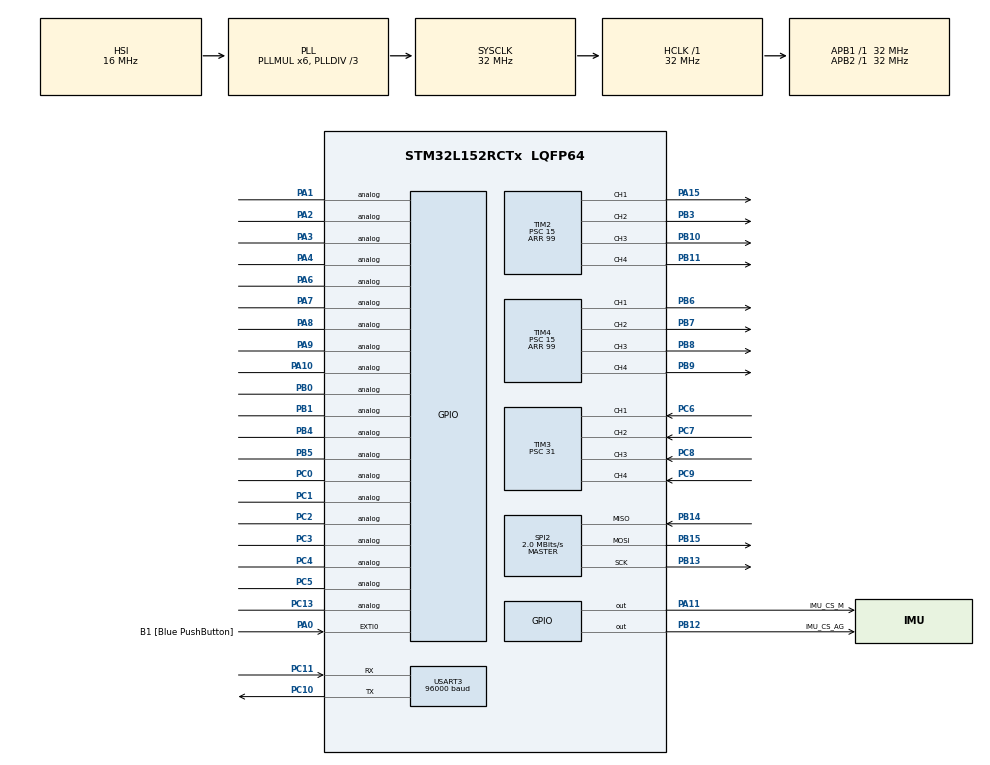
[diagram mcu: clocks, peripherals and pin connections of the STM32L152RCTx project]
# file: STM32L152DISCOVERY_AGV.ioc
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Mcu.Family=STM32L1
Mcu.Name=STM32L152RCTx
Mcu.Package=LQFP64
NVIC.PriorityGroup=NVIC_PRIORITYGROUP_0
NVIC.USART3_IRQn=true\:0\:0\:false\:false\:true\:true\:true\:true
PA0-WKUP1.GPIO_Label=B1 [Blue PushButton]
PA0-WKUP1.GPIO_ModeDefaultEXTI=GPIO_MODE_EVT_RISING
PA0-WKUP1.GPIO_PuPd=GPIO_NOPULL
PA0-WKUP1.Signal=GPXTI0
PA1.Signal=GPIO_Analog
PA10.Signal=GPIO_Analog
PA11.GPIO_Label=IMU_CS_M
PA11.PinState=GPIO_PIN_SET
PA11.Signal=GPIO_Output
PA13.GPIO_Label=SWDIO
PA13.Mode=Serial_Wire
PA13.Signal=SYS_JTMS-SWDIO
PA14.GPIO_Label=SWCLK
PA14.Mode=Serial_Wire
PA14.Signal=SYS_JTCK-SWCLK
PA15.Signal=S_TIM2_CH1_ETR
PA2.Signal=GPIO_Analog
PA3.Signal=GPIO_Analog
PA4.GPIO_Mode=GPIO_MODE_ANALOG
PA4.GPIO_PuPd=GPIO_NOPULL
PA4.Signal=GPIO_Analog
PA6.Signal=GPIO_Analog
PA7.Signal=GPIO_Analog
PA8.Signal=GPIO_Analog
PA9.Signal=GPIO_Analog
PB0.Signal=GPIO_Analog
PB1.Signal=GPIO_Analog
PB10.Signal=S_TIM2_CH3
PB11.Signal=S_TIM2_CH4
PB12.GPIO_Label=IMU_CS_AG
PB12.PinState=GPIO_PIN_SET
PB12.Signal=GPIO_Output
PB13.Mode=Full_Duplex_Master
PB13.Signal=SPI2_SCK
PB14.Mode=Full_Duplex_Master
PB14.Signal=SPI2_MISO
PB15.Mode=Full_Duplex_Master
PB15.Signal=SPI2_MOSI
PB3.Signal=S_TIM2_CH2
PB4.Signal=GPIO_Analog
PB5.Signal=GPIO_Analog
PB6.Signal=S_TIM4_CH1
PB7.Signal=S_TIM4_CH2
PB8.Signal=S_TIM4_CH3
PB9.Signal=S_TIM4_CH4
PC0.Signal=GPIO_Analog
PC1.Signal=GPIO_Analog
PC10.Mode=Asynchronous
PC10.Signal=USART3_TX
PC11.Mode=Asynchronous
PC11.Signal=USART3_RX
PC13-WKUP2.Signal=GPIO_Analog
PC14-OSC32_IN.GPIO_Label=PC14-OSC32_IN
PC14-OSC32_IN.Mode=LSE-External-Oscillator
PC14-OSC32_IN.Signal=RCC_OSC32_IN
PC15-OSC32_OUT.GPIO_Label=PC15-OSC32_OUT
PC15-OSC32_OUT.Mode=LSE-External-Oscillator
PC15-OSC32_OUT.Signal=RCC_OSC32_OUT
PC2.Signal=GPIO_Analog
PC3.Signal=GPIO_Analog
PC4.Signal=GPIO_Analog
PC5.Signal=GPIO_Analog
PC6.Signal=S_TIM3_CH1
PC7.Signal=S_TIM3_CH2
PC8.Signal=S_TIM3_CH3
PC9.Signal=S_TIM3_CH4
ProjectManager.HeapSize=0x200
ProjectManager.StackSize=0x400
ProjectManager.TargetToolchain=CMake
RCC.48MHZClocksFreq_Value=48000000
RCC.AHBFreq_Value=32000000
RCC.APB1Freq_Value=32000000
RCC.APB1TimFreq_Value=32000000
RCC.APB2Freq_Value=32000000
RCC.APB2TimFreq_Value=32000000
RCC.HCLKFreq_Value=32000000
RCC.HSE_VALUE=8000000
RCC.HSI_VALUE=16000000
RCC.MSI_VALUE=2097000
RCC.PLLDIV=RCC_PLL_DIV3
RCC.PLLMUL=RCC_PLL_MUL6
RCC.RTCClockSelectionVirtual=RCC_RTCCLKSOURCE_LSE
RCC.SYSCLKFreq_VALUE=32000000
RCC.SYSCLKSource=RCC_SYSCLKSOURCE_PLLCLK
RCC.USBOutput=48000000
RCC.VCOOutputFreq_Value=96000000
SH.S_TIM2_CH1_ETR.0=TIM2_CH1,PWM Generation1 CH1
SH.S_TIM2_CH2.0=TIM2_CH2,PWM Generation2 CH2
SH.S_TIM2_CH3.0=TIM2_CH3,PWM Generation3 CH3
SH.S_TIM2_CH4.0=TIM2_CH4,PWM Generation4 CH4
SH.S_TIM3_CH1.0=TIM3_CH1,Input_Capture1_from_TI1
SH.S_TIM3_CH2.0=TIM3_CH2,Input_Capture2_from_TI2
SH.S_TIM3_CH3.0=TIM3_CH3,Input_Capture3_from_TI3
SH.S_TIM3_CH4.0=TIM3_CH4,Input_Capture4_from_TI4
SH.S_TIM4_CH1.0=TIM4_CH1,PWM Generation1 CH1
SH.S_TIM4_CH2.0=TIM4_CH2,PWM Generation2 CH2
SH.S_TIM4_CH3.0=TIM4_CH3,PWM Generation3 CH3
SH.S_TIM4_CH4.0=TIM4_CH4,PWM Generation4 CH4
SPI2.BaudRatePrescaler=SPI_BAUDRATEPRESCALER_16
SPI2.CLKPhase=SPI_PHASE_2EDGE
SPI2.CLKPolarity=SPI_POLARITY_HIGH
SPI2.CRCCalculation=SPI_CRCCALCULATION_DISABLE
SPI2.CalculateBaudRate=2.0 MBits/s
SPI2.Direction=SPI_DIRECTION_2LINES
SPI2.Mode=SPI_MODE_MASTER
SPI2.VirtualType=VM_MASTER
TIM2.AutoReloadPreload=TIM_AUTORELOAD_PRELOAD_ENABLE
TIM2.Channel-PWM\ Generation1\ CH1=TIM_CHANNEL_1
TIM2.Channel-PWM\ Generation2\ CH2=TIM_CHANNEL_2
TIM2.Channel-PWM\ Generation3\ CH3=TIM_CHANNEL_3
TIM2.Channel-PWM\ Generation4\ CH4=TIM_CHANNEL_4
TIM2.Period=99
TIM2.Prescaler=15
TIM3.Channel-Input_Capture1_from_TI1=TIM_CHANNEL_1
TIM3.Channel-Input_Capture2_from_TI2=TIM_CHANNEL_2
TIM3.Channel-Input_Capture3_from_TI3=TIM_CHANNEL_3
TIM3.Channel-Input_Capture4_from_TI4=TIM_CHANNEL_4
TIM3.Prescaler=31
TIM4.AutoReloadPreload=TIM_AUTORELOAD_PRELOAD_ENABLE
TIM4.Channel-PWM\ Generation1\ CH1=TIM_CHANNEL_1
TIM4.Channel-PWM\ Generation2\ CH2=TIM_CHANNEL_2
TIM4.Channel-PWM\ Generation3\ CH3=TIM_CHANNEL_3
TIM4.Channel-PWM\ Generation4\ CH4=TIM_CHANNEL_4
TIM4.Period=99
TIM4.Prescaler=15
USART3.BaudRate=96000
USART3.VirtualMode=VM_ASYNC
VP_TIM2_VS_ClockSourceINT.Mode=Internal
VP_TIM3_VS_ClockSourceINT.Mode=Internal
VP_TIM4_VS_ClockSourceINT.Mode=Internal
board=STM32L152C-DISCO

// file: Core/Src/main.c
/* USER CODE BEGIN Header */
/**
  ******************************************************************************
  * @file           : main.c
  * @brief          : Main program body
  ******************************************************************************
  * @attention
  *
  * Copyright (c) 2026 STMicroelectronics.
  * All rights reserved.
  *
  * This software is licensed under terms that can be found in the LICENSE file
  * in the root directory of this software component.
  * If no LICENSE file comes with this software, it is provided AS-IS.
  *
  ******************************************************************************
  */
/* USER CODE END Header */
#include "main.h"

/* USER CODE BEGIN Includes */
#include "board/stm32l152discovery/main_board_stm32l152discovery.hpp"

/* USER CODE END Includes */

SPI_HandleTypeDef hspi2;

TIM_HandleTypeDef htim2;
TIM_HandleTypeDef htim3;
TIM_HandleTypeDef htim4;

UART_HandleTypeDef huart3;

void SystemClock_Config(void);
static void MX_GPIO_Init(void);
static void MX_SPI2_Init(void);
static void MX_TIM2_Init(void);
static void MX_TIM3_Init(void);
static void MX_TIM4_Init(void);
static void MX_USART3_UART_Init(void);

int main(void)
{

  /* MCU Configuration--------------------------------------------------------*/

  /* Reset of all peripherals, Initializes the Flash interface and the Systick. */
  HAL_Init();

  /* Configure the system clock */
  SystemClock_Config();

  /* Initialize all configured peripherals */
  MX_GPIO_Init();
  MX_SPI2_Init();
  MX_TIM2_Init();
  MX_TIM3_Init();
  MX_TIM4_Init();
  MX_USART3_UART_Init();
  /* USER CODE BEGIN 2 */

  HAL_Delay(150);

  board_init();

  /* USER CODE END 2 */

  /* Infinite loop */
  while (1)
  {
    board_tick();

  }
}

void SystemClock_Config(void)
{
  RCC_OscInitTypeDef RCC_OscInitStruct = {0};
  RCC_ClkInitTypeDef RCC_ClkInitStruct = {0};

  /** Configure the main internal regulator output voltage
  */
  __HAL_PWR_VOLTAGESCALING_CONFIG(PWR_REGULATOR_VOLTAGE_SCALE1);

  /** Initializes the RCC Oscillators according to the specified parameters
  * in the RCC_OscInitTypeDef structure.
  */
  RCC_OscInitStruct.OscillatorType = RCC_OSCILLATORTYPE_HSI;
  RCC_OscInitStruct.HSIState = RCC_HSI_ON;
  RCC_OscInitStruct.HSICalibrationValue = RCC_HSICALIBRATION_DEFAULT;
  RCC_OscInitStruct.PLL.PLLState = RCC_PLL_ON;
  RCC_OscInitStruct.PLL.PLLSource = RCC_PLLSOURCE_HSI;
  RCC_OscInitStruct.PLL.PLLMUL = RCC_PLL_MUL6;
  RCC_OscInitStruct.PLL.PLLDIV = RCC_PLL_DIV3;
  if (HAL_RCC_OscConfig(&RCC_OscInitStruct) != HAL_OK)
  {
    Error_Handler();
  }

  /** Initializes the CPU, AHB and APB buses clocks
  */
  RCC_ClkInitStruct.ClockType = RCC_CLOCKTYPE_HCLK|RCC_CLOCKTYPE_SYSCLK
                              |RCC_CLOCKTYPE_PCLK1|RCC_CLOCKTYPE_PCLK2;
  RCC_ClkInitStruct.SYSCLKSource = RCC_SYSCLKSOURCE_PLLCLK;
  RCC_ClkInitStruct.AHBCLKDivider = RCC_SYSCLK_DIV1;
  RCC_ClkInitStruct.APB1CLKDivider = RCC_HCLK_DIV1;
  RCC_ClkInitStruct.APB2CLKDivider = RCC_HCLK_DIV1;

  if (HAL_RCC_ClockConfig(&RCC_ClkInitStruct, FLASH_LATENCY_1) != HAL_OK)
  {
    Error_Handler();
  }
}

static void MX_SPI2_Init(void)
{

  /* SPI2 parameter configuration*/
  hspi2.Instance = SPI2;
  hspi2.Init.Mode = SPI_MODE_MASTER;
  hspi2.Init.Direction = SPI_DIRECTION_2LINES;
  hspi2.Init.DataSize = SPI_DATASIZE_8BIT;
  hspi2.Init.CLKPolarity = SPI_POLARITY_HIGH;
  hspi2.Init.CLKPhase = SPI_PHASE_2EDGE;
  hspi2.Init.NSS = SPI_NSS_SOFT;
  hspi2.Init.BaudRatePrescaler = SPI_BAUDRATEPRESCALER_16;
  hspi2.Init.FirstBit = SPI_FIRSTBIT_MSB;
  hspi2.Init.TIMode = SPI_TIMODE_DISABLE;
  hspi2.Init.CRCCalculation = SPI_CRCCALCULATION_DISABLE;
  hspi2.Init.CRCPolynomial = 10;
  if (HAL_SPI_Init(&hspi2) != HAL_OK)
  {
    Error_Handler();
  }

}

static void MX_TIM2_Init(void)
{

  TIM_ClockConfigTypeDef sClockSourceConfig = {0};
  TIM_MasterConfigTypeDef sMasterConfig = {0};
  TIM_OC_InitTypeDef sConfigOC = {0};

  htim2.Instance = TIM2;
  htim2.Init.Prescaler = 15;
  htim2.Init.CounterMode = TIM_COUNTERMODE_UP;
  htim2.Init.Period = 99;
  htim2.Init.ClockDivision = TIM_CLOCKDIVISION_DIV1;
  htim2.Init.AutoReloadPreload = TIM_AUTORELOAD_PRELOAD_ENABLE;
  if (HAL_TIM_Base_Init(&htim2) != HAL_OK)
  {
    Error_Handler();
  }
  sClockSourceConfig.ClockSource = TIM_CLOCKSOURCE_INTERNAL;
  if (HAL_TIM_ConfigClockSource(&htim2, &sClockSourceConfig) != HAL_OK)
  {
    Error_Handler();
  }
  if (HAL_TIM_PWM_Init(&htim2) != HAL_OK)
  {
    Error_Handler();
  }
  sMasterConfig.MasterOutputTrigger = TIM_TRGO_RESET;
  sMasterConfig.MasterSlaveMode = TIM_MASTERSLAVEMODE_DISABLE;
  if (HAL_TIMEx_MasterConfigSynchronization(&htim2, &sMasterConfig) != HAL_OK)
  {
    Error_Handler();
  }
  sConfigOC.OCMode = TIM_OCMODE_PWM1;
  sConfigOC.Pulse = 0;
  sConfigOC.OCPolarity = TIM_OCPOLARITY_HIGH;
  sConfigOC.OCFastMode = TIM_OCFAST_DISABLE;
  if (HAL_TIM_PWM_ConfigChannel(&htim2, &sConfigOC, TIM_CHANNEL_1) != HAL_OK)
  {
    Error_Handler();
  }
  if (HAL_TIM_PWM_ConfigChannel(&htim2, &sConfigOC, TIM_CHANNEL_2) != HAL_OK)
  {
    Error_Handler();
  }
  if (HAL_TIM_PWM_ConfigChannel(&htim2, &sConfigOC, TIM_CHANNEL_3) != HAL_OK)
  {
    Error_Handler();
  }
  if (HAL_TIM_PWM_ConfigChannel(&htim2, &sConfigOC, TIM_CHANNEL_4) != HAL_OK)
  {
    Error_Handler();
  }
  HAL_TIM_MspPostInit(&htim2);

}

static void MX_TIM3_Init(void)
{

  TIM_ClockConfigTypeDef sClockSourceConfig = {0};
  TIM_MasterConfigTypeDef sMasterConfig = {0};
  TIM_IC_InitTypeDef sConfigIC = {0};

  htim3.Instance = TIM3;
  htim3.Init.Prescaler = 31;
  htim3.Init.CounterMode = TIM_COUNTERMODE_UP;
  htim3.Init.Period = 65535;
  htim3.Init.ClockDivision = TIM_CLOCKDIVISION_DIV1;
  htim3.Init.AutoReloadPreload = TIM_AUTORELOAD_PRELOAD_DISABLE;
  if (HAL_TIM_Base_Init(&htim3) != HAL_OK)
  {
    Error_Handler();
  }
  sClockSourceConfig.ClockSource = TIM_CLOCKSOURCE_INTERNAL;
  if (HAL_TIM_ConfigClockSource(&htim3, &sClockSourceConfig) != HAL_OK)
  {
    Error_Handler();
  }
  if (HAL_TIM_IC_Init(&htim3) != HAL_OK)
  {
    Error_Handler();
  }
  sMasterConfig.MasterOutputTrigger = TIM_TRGO_RESET;
  sMasterConfig.MasterSlaveMode = TIM_MASTERSLAVEMODE_DISABLE;
  if (HAL_TIMEx_MasterConfigSynchronization(&htim3, &sMasterConfig) != HAL_OK)
  {
    Error_Handler();
  }
  sConfigIC.ICPolarity = TIM_INPUTCHANNELPOLARITY_RISING;
  sConfigIC.ICSelection = TIM_ICSELECTION_DIRECTTI;
  sConfigIC.ICPrescaler = TIM_ICPSC_DIV1;
  sConfigIC.ICFilter = 0;
  if (HAL_TIM_IC_ConfigChannel(&htim3, &sConfigIC, TIM_CHANNEL_1) != HAL_OK)
  {
    Error_Handler();
  }
  if (HAL_TIM_IC_ConfigChannel(&htim3, &sConfigIC, TIM_CHANNEL_2) != HAL_OK)
  {
    Error_Handler();
  }
  if (HAL_TIM_IC_ConfigChannel(&htim3, &sConfigIC, TIM_CHANNEL_3) != HAL_OK)
  {
    Error_Handler();
  }
  if (HAL_TIM_IC_ConfigChannel(&htim3, &sConfigIC, TIM_CHANNEL_4) != HAL_OK)
  {
    Error_Handler();
  }

}

static void MX_TIM4_Init(void)
{

  TIM_ClockConfigTypeDef sClockSourceConfig = {0};
  TIM_MasterConfigTypeDef sMasterConfig = {0};
  TIM_OC_InitTypeDef sConfigOC = {0};

  htim4.Instance = TIM4;
  htim4.Init.Prescaler = 15;
  htim4.Init.CounterMode = TIM_COUNTERMODE_UP;
  htim4.Init.Period = 99;
  htim4.Init.ClockDivision = TIM_CLOCKDIVISION_DIV1;
  htim4.Init.AutoReloadPreload = TIM_AUTORELOAD_PRELOAD_ENABLE;
  if (HAL_TIM_Base_Init(&htim4) != HAL_OK)
  {
    Error_Handler();
  }
  sClockSourceConfig.ClockSource = TIM_CLOCKSOURCE_INTERNAL;
  if (HAL_TIM_ConfigClockSource(&htim4, &sClockSourceConfig) != HAL_OK)
  {
    Error_Handler();
  }
  if (HAL_TIM_PWM_Init(&htim4) != HAL_OK)
  {
    Error_Handler();
  }
  sMasterConfig.MasterOutputTrigger = TIM_TRGO_RESET;
  sMasterConfig.MasterSlaveMode = TIM_MASTERSLAVEMODE_DISABLE;
  if (HAL_TIMEx_MasterConfigSynchronization(&htim4, &sMasterConfig) != HAL_OK)
  {
    Error_Handler();
  }
  sConfigOC.OCMode = TIM_OCMODE_PWM1;
  sConfigOC.Pulse = 0;
  sConfigOC.OCPolarity = TIM_OCPOLARITY_HIGH;
  sConfigOC.OCFastMode = TIM_OCFAST_DISABLE;
  if (HAL_TIM_PWM_ConfigChannel(&htim4, &sConfigOC, TIM_CHANNEL_1) != HAL_OK)
  {
    Error_Handler();
  }
  if (HAL_TIM_PWM_ConfigChannel(&htim4, &sConfigOC, TIM_CHANNEL_2) != HAL_OK)
  {
    Error_Handler();
  }
  if (HAL_TIM_PWM_ConfigChannel(&htim4, &sConfigOC, TIM_CHANNEL_3) != HAL_OK)
  {
    Error_Handler();
  }
  if (HAL_TIM_PWM_ConfigChannel(&htim4, &sConfigOC, TIM_CHANNEL_4) != HAL_OK)
  {
    Error_Handler();
  }
  HAL_TIM_MspPostInit(&htim4);

}

static void MX_USART3_UART_Init(void)
{

  huart3.Instance = USART3;
  huart3.Init.BaudRate = 115200;
  huart3.Init.WordLength = UART_WORDLENGTH_8B;
  huart3.Init.StopBits = UART_STOPBITS_1;
  huart3.Init.Parity = UART_PARITY_NONE;
  huart3.Init.Mode = UART_MODE_TX_RX;
  huart3.Init.HwFlowCtl = UART_HWCONTROL_NONE;
  huart3.Init.OverSampling = UART_OVERSAMPLING_16;
  if (HAL_UART_Init(&huart3) != HAL_OK)
  {
    Error_Handler();
  }

}

static void MX_GPIO_Init(void)
{
  GPIO_InitTypeDef GPIO_InitStruct = {0};

  /* GPIO Ports Clock Enable */
  __HAL_RCC_GPIOC_CLK_ENABLE();
  __HAL_RCC_GPIOA_CLK_ENABLE();
  __HAL_RCC_GPIOB_CLK_ENABLE();

  /*Configure GPIO pin Output Level */
  HAL_GPIO_WritePin(IMU_CS_AG_GPIO_Port, IMU_CS_AG_Pin, GPIO_PIN_SET);

  /*Configure GPIO pin Output Level */
  HAL_GPIO_WritePin(IMU_CS_M_GPIO_Port, IMU_CS_M_Pin, GPIO_PIN_SET);

  /*Configure GPIO pins : PC13 PC0 PC1 PC2
                           PC3 PC4 PC5 */
  GPIO_InitStruct.Pin = GPIO_PIN_13|GPIO_PIN_0|GPIO_PIN_1|GPIO_PIN_2
                          |GPIO_PIN_3|GPIO_PIN_4|GPIO_PIN_5;
  GPIO_InitStruct.Mode = GPIO_MODE_ANALOG;
  GPIO_InitStruct.Pull = GPIO_NOPULL;
  HAL_GPIO_Init(GPIOC, &GPIO_InitStruct);

  /*Configure GPIO pin : B1_Pin */
  GPIO_InitStruct.Pin = B1_Pin;
  GPIO_InitStruct.Mode = GPIO_MODE_EVT_RISING;
  GPIO_InitStruct.Pull = GPIO_NOPULL;
  HAL_GPIO_Init(B1_GPIO_Port, &GPIO_InitStruct);

  /*Configure GPIO pins : PA1 PA2 PA3 PA4
                           PA6 PA7 PA8 PA9
                           PA10 */
  GPIO_InitStruct.Pin = GPIO_PIN_1|GPIO_PIN_2|GPIO_PIN_3|GPIO_PIN_4
                          |GPIO_PIN_6|GPIO_PIN_7|GPIO_PIN_8|GPIO_PIN_9
                          |GPIO_PIN_10;
  GPIO_InitStruct.Mode = GPIO_MODE_ANALOG;
  GPIO_InitStruct.Pull = GPIO_NOPULL;
  HAL_GPIO_Init(GPIOA, &GPIO_InitStruct);

  /*Configure GPIO pins : PB0 PB1 PB4 PB5 */
  GPIO_InitStruct.Pin = GPIO_PIN_0|GPIO_PIN_1|GPIO_PIN_4|GPIO_PIN_5;
  GPIO_InitStruct.Mode = GPIO_MODE_ANALOG;
  GPIO_InitStruct.Pull = GPIO_NOPULL;
  HAL_GPIO_Init(GPIOB, &GPIO_InitStruct);

  /*Configure GPIO pin : IMU_CS_AG_Pin */
  GPIO_InitStruct.Pin = IMU_CS_AG_Pin;
  GPIO_InitStruct.Mode = GPIO_MODE_OUTPUT_PP;
  GPIO_InitStruct.Pull = GPIO_NOPULL;
  GPIO_InitStruct.Speed = GPIO_SPEED_FREQ_LOW;
  HAL_GPIO_Init(IMU_CS_AG_GPIO_Port, &GPIO_InitStruct);

  /*Configure GPIO pin : IMU_CS_M_Pin */
  GPIO_InitStruct.Pin = IMU_CS_M_Pin;
  GPIO_InitStruct.Mode = GPIO_MODE_OUTPUT_PP;
  GPIO_InitStruct.Pull = GPIO_NOPULL;
  GPIO_InitStruct.Speed = GPIO_SPEED_FREQ_LOW;
  HAL_GPIO_Init(IMU_CS_M_GPIO_Port, &GPIO_InitStruct);

}

void Error_Handler(void)
{
  __disable_irq();
  while (1)
  {
  }
}
